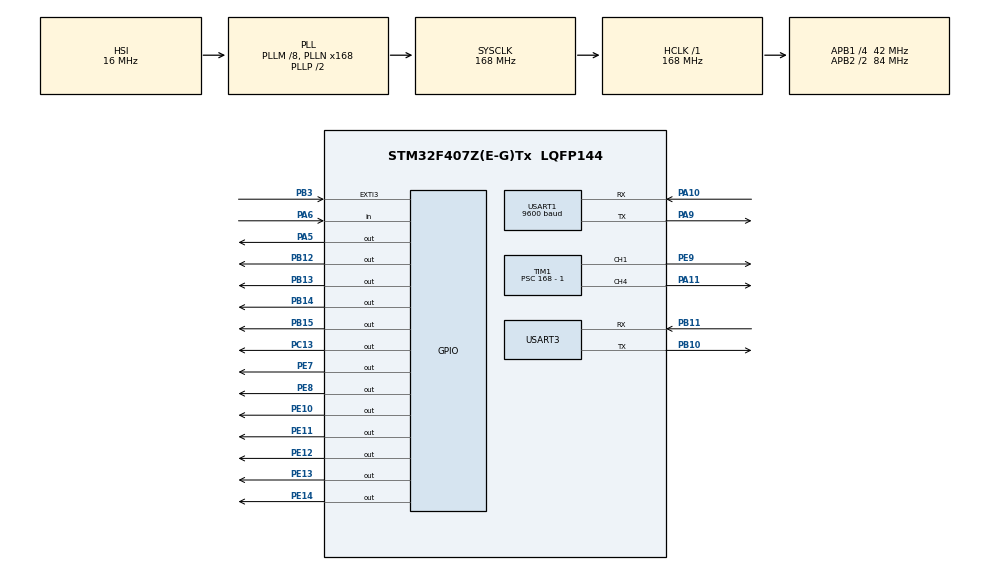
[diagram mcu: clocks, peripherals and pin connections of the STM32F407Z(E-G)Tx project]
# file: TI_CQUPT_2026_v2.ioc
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Dma.Request0=USART1_RX
Dma.USART1_RX.0.Direction=DMA_PERIPH_TO_MEMORY
Dma.USART1_RX.0.FIFOMode=DMA_FIFOMODE_DISABLE
Dma.USART1_RX.0.Instance=DMA2_Stream2
Dma.USART1_RX.0.MemDataAlignment=DMA_MDATAALIGN_BYTE
Dma.USART1_RX.0.MemInc=DMA_MINC_ENABLE
Dma.USART1_RX.0.Mode=DMA_NORMAL
Dma.USART1_RX.0.PeriphDataAlignment=DMA_PDATAALIGN_BYTE
Dma.USART1_RX.0.PeriphInc=DMA_PINC_DISABLE
Dma.USART1_RX.0.Priority=DMA_PRIORITY_LOW
Mcu.Family=STM32F4
Mcu.Name=STM32F407Z(E-G)Tx
Mcu.Package=LQFP144
NVIC.DMA2_Stream2_IRQn=true\:5\:0\:true\:false\:true\:false\:true\:true
NVIC.EXTI3_IRQn=true\:1\:0\:true\:false\:true\:true\:true\:true
NVIC.PriorityGroup=NVIC_PRIORITYGROUP_4
NVIC.USART1_IRQn=true\:5\:0\:true\:false\:true\:true\:true\:true
PA10.Mode=Asynchronous
PA10.Signal=USART1_RX
PA11.Signal=S_TIM1_CH4
PA13.Mode=Serial_Wire
PA13.Signal=SYS_JTMS-SWDIO
PA14.Mode=Serial_Wire
PA14.Signal=SYS_JTCK-SWCLK
PA5.GPIO_Speed=GPIO_SPEED_FREQ_VERY_HIGH
PA5.PinState=GPIO_PIN_SET
PA5.Signal=GPIO_Output
PA6.GPIO_PuPd=GPIO_PULLUP
PA6.Signal=GPIO_Input
PA9.Mode=Asynchronous
PA9.Signal=USART1_TX
PB10.Mode=Asynchronous
PB10.Signal=USART3_TX
PB11.Mode=Asynchronous
PB11.Signal=USART3_RX
PB12.GPIO_Speed=GPIO_SPEED_FREQ_HIGH
PB12.Signal=GPIO_Output
PB13.GPIO_Speed=GPIO_SPEED_FREQ_HIGH
PB13.Signal=GPIO_Output
PB14.GPIO_Speed=GPIO_SPEED_FREQ_HIGH
PB14.Signal=GPIO_Output
PB15.GPIO_Speed=GPIO_SPEED_FREQ_HIGH
PB15.Signal=GPIO_Output
PB3.GPIO_ModeDefaultEXTI=GPIO_MODE_IT_FALLING
PB3.Signal=GPXTI3
PC13-ANTI_TAMP.Signal=GPIO_Output
PE10.GPIO_Speed=GPIO_SPEED_FREQ_VERY_HIGH
PE10.PinState=GPIO_PIN_SET
PE10.Signal=GPIO_Output
PE11.Signal=GPIO_Output
PE12.Signal=GPIO_Output
PE13.Signal=GPIO_Output
PE14.Signal=GPIO_Output
PE7.Signal=GPIO_Output
PE8.GPIO_Speed=GPIO_SPEED_FREQ_VERY_HIGH
PE8.PinState=GPIO_PIN_SET
PE8.Signal=GPIO_Output
PE9.Signal=S_TIM1_CH1
PH0-OSC_IN.Mode=HSE-External-Oscillator
PH0-OSC_IN.Signal=RCC_OSC_IN
PH1-OSC_OUT.Mode=HSE-External-Oscillator
PH1-OSC_OUT.Signal=RCC_OSC_OUT
ProjectManager.HeapSize=0x200
ProjectManager.StackSize=0x400
ProjectManager.TargetToolchain=MDK-ARM V5.32
RCC.48MHZClocksFreq_Value=84000000
RCC.AHBFreq_Value=168000000
RCC.APB1CLKDivider=RCC_HCLK_DIV4
RCC.APB1Freq_Value=42000000
RCC.APB1TimFreq_Value=84000000
RCC.APB2CLKDivider=RCC_HCLK_DIV2
RCC.APB2Freq_Value=84000000
RCC.APB2TimFreq_Value=168000000
RCC.CortexFreq_Value=168000000
RCC.HCLKFreq_Value=168000000
RCC.HSE_VALUE=25000000
RCC.HSI_VALUE=16000000
RCC.LSE_VALUE=32768
RCC.PLLM=8
RCC.PLLN=168
RCC.SYSCLKFreq_VALUE=168000000
RCC.SYSCLKSource=RCC_SYSCLKSOURCE_PLLCLK
RCC.VCOOutputFreq_Value=336000000
SH.S_TIM1_CH1.0=TIM1_CH1,PWM Generation1 CH1
SH.S_TIM1_CH4.0=TIM1_CH4,PWM Generation4 CH4
STMicroelectronics.X-CUBE-ALGOBUILD.1.4.0.LibraryCcDSPOoLibraryJjDSPOoLibrary=true
TIM1.Channel-PWM\ Generation1\ CH1=TIM_CHANNEL_1
TIM1.Channel-PWM\ Generation4\ CH4=TIM_CHANNEL_4
TIM1.Period=100 - 1
TIM1.Prescaler=168 - 1
TIM1.Pulse-PWM\ Generation1\ CH1=50
TIM1.Pulse-PWM\ Generation4\ CH4=50
USART1.BaudRate=9600
USART1.VirtualMode=VM_ASYNC
USART3.VirtualMode=VM_ASYNC
VP_STMicroelectronics.X-CUBE-ALGOBUILD_VS_DSPOoLibraryJjLibrary_1.4.0_1.4.0.Mode=DSPOoLibraryJjLibrary
VP_TIM1_VS_ClockSourceINT.Mode=Internal
board=custom

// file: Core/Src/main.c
/* USER CODE BEGIN Header */
/**
 ******************************************************************************
 * @file           : main.c
 * @brief          : Main program body
 ******************************************************************************
 * @attention
 *
 * Copyright (c) 2026 STMicroelectronics.
 * All rights reserved.
 *
 * This software is licensed under terms that can be found in the LICENSE file
 * in the root directory of this software component.
 * If no LICENSE file comes with this software, it is provided AS-IS.
 *
 ******************************************************************************
 */
/* USER CODE END Header */
#include "main.h"
#include "dma.h"
#include "tim.h"
#include "usart.h"
#include "gpio.h"

/* USER CODE BEGIN Includes */
#include "app_process.h"
#include "bsp_AD7606.h"
#include "bsp_AD9833.h"
/* USER CODE END Includes */

void SystemClock_Config(void);

int main(void)
{

  /* MCU Configuration--------------------------------------------------------*/

  /* Reset of all peripherals, Initializes the Flash interface and the Systick. */
  HAL_Init();

  /* Configure the system clock */
  SystemClock_Config();

  /* Initialize all configured peripherals */
  MX_GPIO_Init();
  MX_DMA_Init();
  MX_USART1_UART_Init();
  MX_USART3_UART_Init();
  MX_TIM1_Init();
  /* USER CODE BEGIN 2 */
  Debug_printf("------SYSTEM BOOT------\r\n");
  AD7606_Init();
  HMI_Process_Init();
	AD9833_WaveSeting(0, 0, SIN_WAVE, 0);
  AD9833_AmpSet(0);
	HAL_Delay(200);
  AD9833_WaveSeting(10000.0, 0, SIN_WAVE, 0);
  AD9833_AmpSet(10);
  Debug_printf("------Init finished:start sample------\r\n");
  /* USER CODE END 2 */

  /* Infinite loop */
  /* USER CODE BEGIN WHILE */
  while (1)
  {
    // AD7606_Sample_Task();
    App_Main_Process_Poll();
    /**
     *待提添加调试指令
     */
    /* USER CODE END WHILE */

  }
}

void SystemClock_Config(void)
{
  RCC_OscInitTypeDef RCC_OscInitStruct = {0};
  RCC_ClkInitTypeDef RCC_ClkInitStruct = {0};

  /** Configure the main internal regulator output voltage
   */
  __HAL_RCC_PWR_CLK_ENABLE();
  __HAL_PWR_VOLTAGESCALING_CONFIG(PWR_REGULATOR_VOLTAGE_SCALE1);

  /** Initializes the RCC Oscillators according to the specified parameters
   * in the RCC_OscInitTypeDef structure.
   */
  RCC_OscInitStruct.OscillatorType = RCC_OSCILLATORTYPE_HSI;
  RCC_OscInitStruct.HSIState = RCC_HSI_ON;
  RCC_OscInitStruct.HSICalibrationValue = RCC_HSICALIBRATION_DEFAULT;
  RCC_OscInitStruct.PLL.PLLState = RCC_PLL_ON;
  RCC_OscInitStruct.PLL.PLLSource = RCC_PLLSOURCE_HSI;
  RCC_OscInitStruct.PLL.PLLM = 8;
  RCC_OscInitStruct.PLL.PLLN = 168;
  RCC_OscInitStruct.PLL.PLLP = RCC_PLLP_DIV2;
  RCC_OscInitStruct.PLL.PLLQ = 4;
  if (HAL_RCC_OscConfig(&RCC_OscInitStruct) != HAL_OK)
  {
    Error_Handler();
  }

  /** Initializes the CPU, AHB and APB buses clocks
   */
  RCC_ClkInitStruct.ClockType = RCC_CLOCKTYPE_HCLK | RCC_CLOCKTYPE_SYSCLK | RCC_CLOCKTYPE_PCLK1 | RCC_CLOCKTYPE_PCLK2;
  RCC_ClkInitStruct.SYSCLKSource = RCC_SYSCLKSOURCE_PLLCLK;
  RCC_ClkInitStruct.AHBCLKDivider = RCC_SYSCLK_DIV1;
  RCC_ClkInitStruct.APB1CLKDivider = RCC_HCLK_DIV4;
  RCC_ClkInitStruct.APB2CLKDivider = RCC_HCLK_DIV2;

  if (HAL_RCC_ClockConfig(&RCC_ClkInitStruct, FLASH_LATENCY_5) != HAL_OK)
  {
    Error_Handler();
  }
}

void Error_Handler(void)
{
  __disable_irq();
  while (1)
  {
  }
}
